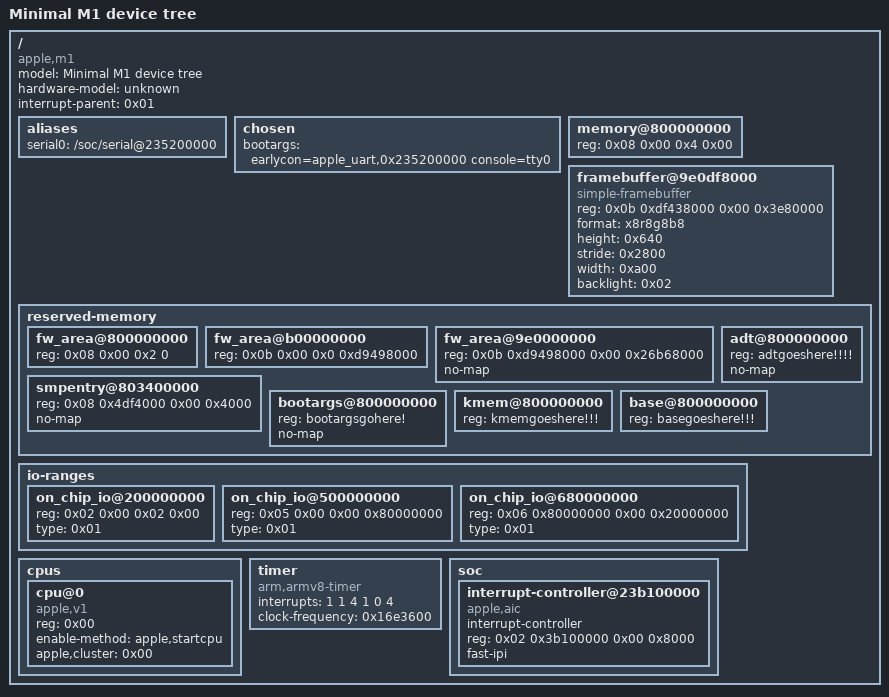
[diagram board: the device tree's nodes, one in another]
/dts-v1/;

/ {
	model = "Minimal M1 device tree";
	compatible = "apple,m1";
	hardware-model = "unknown";
	interrupt-parent = <0x01>;
	#address-cells = <0x02>;
	#size-cells = <0x02>;

	aliases {
		serial0 = "/soc/serial@235200000";
	};

	chosen {
		bootargs = "earlycon=apple_uart,0x235200000 console=tty0";
	};

	memory@800000000 {
		device_type = "memory";
		reg = <0x08 0x00 0x4 0x00>;
	};

	framebuffer@9e0df8000 {
		compatible = "simple-framebuffer";
		reg = <0x0b 0xdf438000 0x00 0x3e80000>;
		format = "x8r8g8b8";
		height = <0x640>;
		stride = <0x2800>;
		width = <0xa00>;
		status = "okay";
		backlight = <0x02>;
	};

	reserved-memory {
		#address-cells = <0x02>;
		#size-cells = <0x02>;
		ranges;

		fw_area@800000000 {
			reg = <0x08 0x00 0x2 0>;
		};

		fw_area@b00000000 {
			reg = <0x0b 0x00 0x0 0xd9498000>;
		};

		fw_area@9e0000000 {
			reg = <0x0b 0xd9498000 0x00 0x26b68000>;
			no-map;
		};

		smpentry@803400000 {
			reg = <0x08 0x4df4000 0x00 0x4000>;
			no-map;
		};

		adt@800000000 {
			reg = "adtgoeshere!!!!";
			no-map;
		};

		bootargs@800000000 {
			reg = "bootargsgohere!";
			no-map;
		};

		kmem@800000000 {
			reg = "kmemgoeshere!!!";
		};

		base@800000000 {
			reg = "basegoeshere!!!";
		};
	};

	io-ranges {
		#address-cells = <0x02>;
		#size-cells = <0x02>;
		ranges;

		on_chip_io@200000000 {
			reg = <0x02 0x00 0x02 0x00>;
			type = <0x01>;
		};

		on_chip_io@500000000 {
			reg = <0x05 0x00 0x00 0x80000000>;
			type = <0x01>;
		};

		on_chip_io@680000000 {
			reg = <0x06 0x80000000 0x00 0x20000000>;
			type = <0x01>;
		};
	};

	cpus {
		#address-cells = <0x01>;
		#size-cells = <0x00>;

		cpu@0 {
			device_type = "cpu";
			compatible = "apple,v1";
			reg = <0x00>;
			enable-method = "apple,startcpu";
			apple,cluster = <0x00>;
		};
	};

	timer {
		compatible = "arm,armv8-timer";
		interrupts = <1 1 4 1 0 4>;
		clock-frequency = <0x16e3600>;
	};

	soc {
		interrupt-controller@23b100000 {
			compatible = "apple,aic";
			#interrupt-cells = <0x03>;
			interrupt-controller;
			reg = <0x02 0x3b100000 0x00 0x8000>;
			fast-ipi;
			phandle = <0x01>;
		};
	};
};
